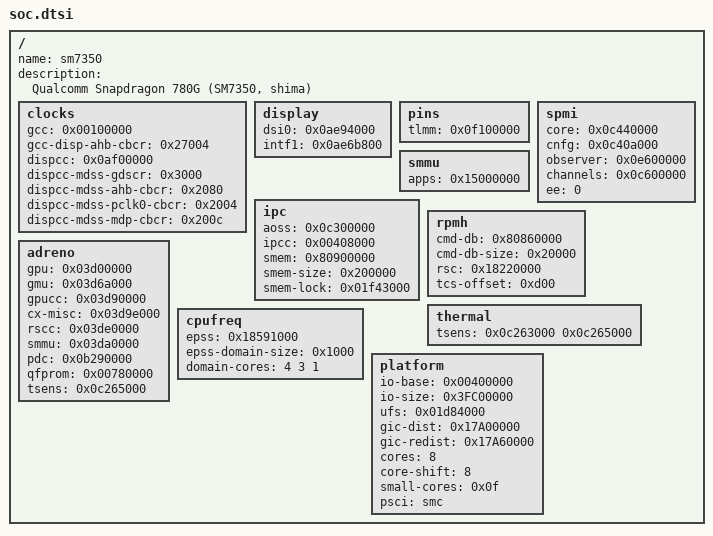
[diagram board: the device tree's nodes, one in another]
/dts-v1/;

// Qualcomm Snapdragon 780G. What every board with this SoC shares: where its blocks are.
// Sources: the SoC's device tree (shima*.dtsi) and Linux's clock drivers (dispcc-shima.c).
/ {
	name = "sm7350";
	description = "Qualcomm Snapdragon 780G (SM7350, shima)";

	// The clocks the display block's registers need before they can be read (Documentation/porting.md, "Display").
	clocks {
		gcc = <0x00100000>;             // clock-controller@100000
		gcc-disp-ahb-cbcr = <0x27004>;  // gcc_disp_ahb_clk
		dispcc = <0x0af00000>;          // clock-controller@af00000
		dispcc-mdss-gdscr = <0x3000>;   // the display block's power switch (mdss_core_gdsc)
		dispcc-mdss-ahb-cbcr = <0x2080>; // disp_cc_mdss_ahb_clk
		dispcc-mdss-pclk0-cbcr = <0x2004>; // disp_cc_mdss_pclk0_clk  } only looked at, by display_probe=1
		dispcc-mdss-mdp-cbcr = <0x200c>; // disp_cc_mdss_mdp_clk    }
	};

	display {
		dsi0 = <0x0ae94000>;            // mdss_dsi0, reg "dsi_ctrl" (DSI controller 2.5)
		intf1 = <0x0ae6b800>;           // mdss_dsi0, reg "mdp_intf_base": the interface the panel hangs on
	};

	// The SoC's own pins (TLMM, pinctrl@f000000): what the drivers of the touch controller, the speaker
	// amplifier, the haptic motor and the cameras drive.
	pins {
		tlmm = <0x0f100000>;            // GPIO 0's registers: 0x100000 into the block; 0x1000 for each GPIO
	};

	// The PMIC arbiter: the way to the power management chips on the SPMI bus (qcom,spmi-pmic-arb, by
	// reg-names "core", "cnfg", "obsrvr" and "chnls"). The keys are read through it; the flashlight and the
	// cameras' supply switch are written through it.
	spmi {
		core = <0x0c440000>;            // the version, and which peripheral each channel is
		cnfg = <0x0c40a000>;            // which system may write through each channel
		observer = <0x0e600000>;        // reads
		channels = <0x0c600000>;        // writes
		ee = <0>;                       // qcom,ee: which of the arbiter's systems this one is
	};

	// The SMMU between the SoC's devices and memory (the GPU has its own, in adreno { }).
	smmu {
		apps = <0x15000000>;            // apps_smmu
	};

	// The way to the SoC's other processors: the audio DSP and the Wi-Fi radio are reached through these.
	ipc {
		aoss = <0x0c300000>;            // qmp_aop (qcom,qmp-mbox): the always-on processor's mailbox
		ipcc = <0x00408000>;            // ipcc_mproc (qcom,ipcc): what the processors ring each other through
		smem = <0x80900000>;            // smem_mem: the memory they share
		smem-size = <0x200000>;
		smem-lock = <0x01f43000>;       // tcsr_mutex 3 (0x1f40000 + 3 x 0x1000): the lock on its allocations
	};

	// RPMh, for the memory bandwidth vote (feature "ddr-rpmh").
	rpmh {
		cmd-db = <0x80860000>;          // reserved-memory, compatible "qcom,cmd-db": the resources' names and addresses
		cmd-db-size = <0x20000>;
		rsc = <0x18220000>;             // apps_rsc (qcom,rpmh-rsc), reg "drv-2": the application processor's sequencer
		tcs-offset = <0xd00>;           // qcom,tcs-offset
	};

	// The Adreno's blocks, for the feature "gpu-a660" (qcom,kgsl-3d0 and qcom,gmu, by their reg-names).
	// What differs from one phone to the next -- the chip, its fuses, its speeds -- is the board's gpu { }.
	adreno {
		gpu = <0x03d00000>;             // qcom,kgsl-3d0, reg "kgsl_3d0_reg_memory": the 3D core
		gmu = <0x03d6a000>;             // qcom,gmu, reg "kgsl_gmu_reg"
		gpucc = <0x03d90000>;           // the GPU's clock controller (clock-controller@3d90000)
		cx-misc = <0x03d9e000>;         // qcom,kgsl-3d0, reg "cx-misc"
		rscc = <0x03de0000>;            // qcom,kgsl-3d0, reg "rscc": the GMU's RPMh channel
		smmu = <0x03da0000>;            // the GPU's SMMU (kgsl-smmu@3da0000)
		pdc = <0x0b290000>;             // qcom,gmu, reg "kgsl_gmu_pdc_cfg"
		qfprom = <0x00780000>;          // the fuses (qfprom@780000), where the board's gpu { } finds its bins
		tsens = <0x0c265000>;           // the TSENS controller with the GPU's two sensors (gpuss-0, gpuss-1)
	};

	thermal {
		tsens = <0x0c263000 0x0c265000>; // tsens0 and tsens1, reg "tsens_tm_physical"
	};

	cpufreq {
		epss = <0x18591000>;            // cpufreq-hw: one block of registers a group of cores
		epss-domain-size = <0x1000>;
		domain-cores = <4 3 1>;         // the cores of each group, in the cores' order (qcom,freq-domain): small, big, prime
	};

	// What the loader tells the kernel of the machine (arch/arm64/boot/src/platform.h, struct platform).
	platform {
		io-base = <0x00400000>;         // one window over the SoC's peripherals; never 0
		io-size = <0x3FC00000>;
		ufs = <0x01d84000>;             // ufshc@1d84000, reg "ufs_mem": the UFS host controller
		gic-dist = <0x17A00000>;        // interrupt-controller@17a00000 (arm,gic-v3): reg, first entry
		gic-redist = <0x17A60000>;      // ... second entry
		cores = <8>;                    // the cpu@ nodes
		core-shift = <8>;               // their reg is 0x000, 0x100 ...: MPIDR's second affinity field
		small-cores = <0x0f>;           // a bit a core of the lowest capacity-dmips-mhz: cores 0 to 3 (Cortex-A55)
		psci = "smc";                   // psci: method
	};
};
